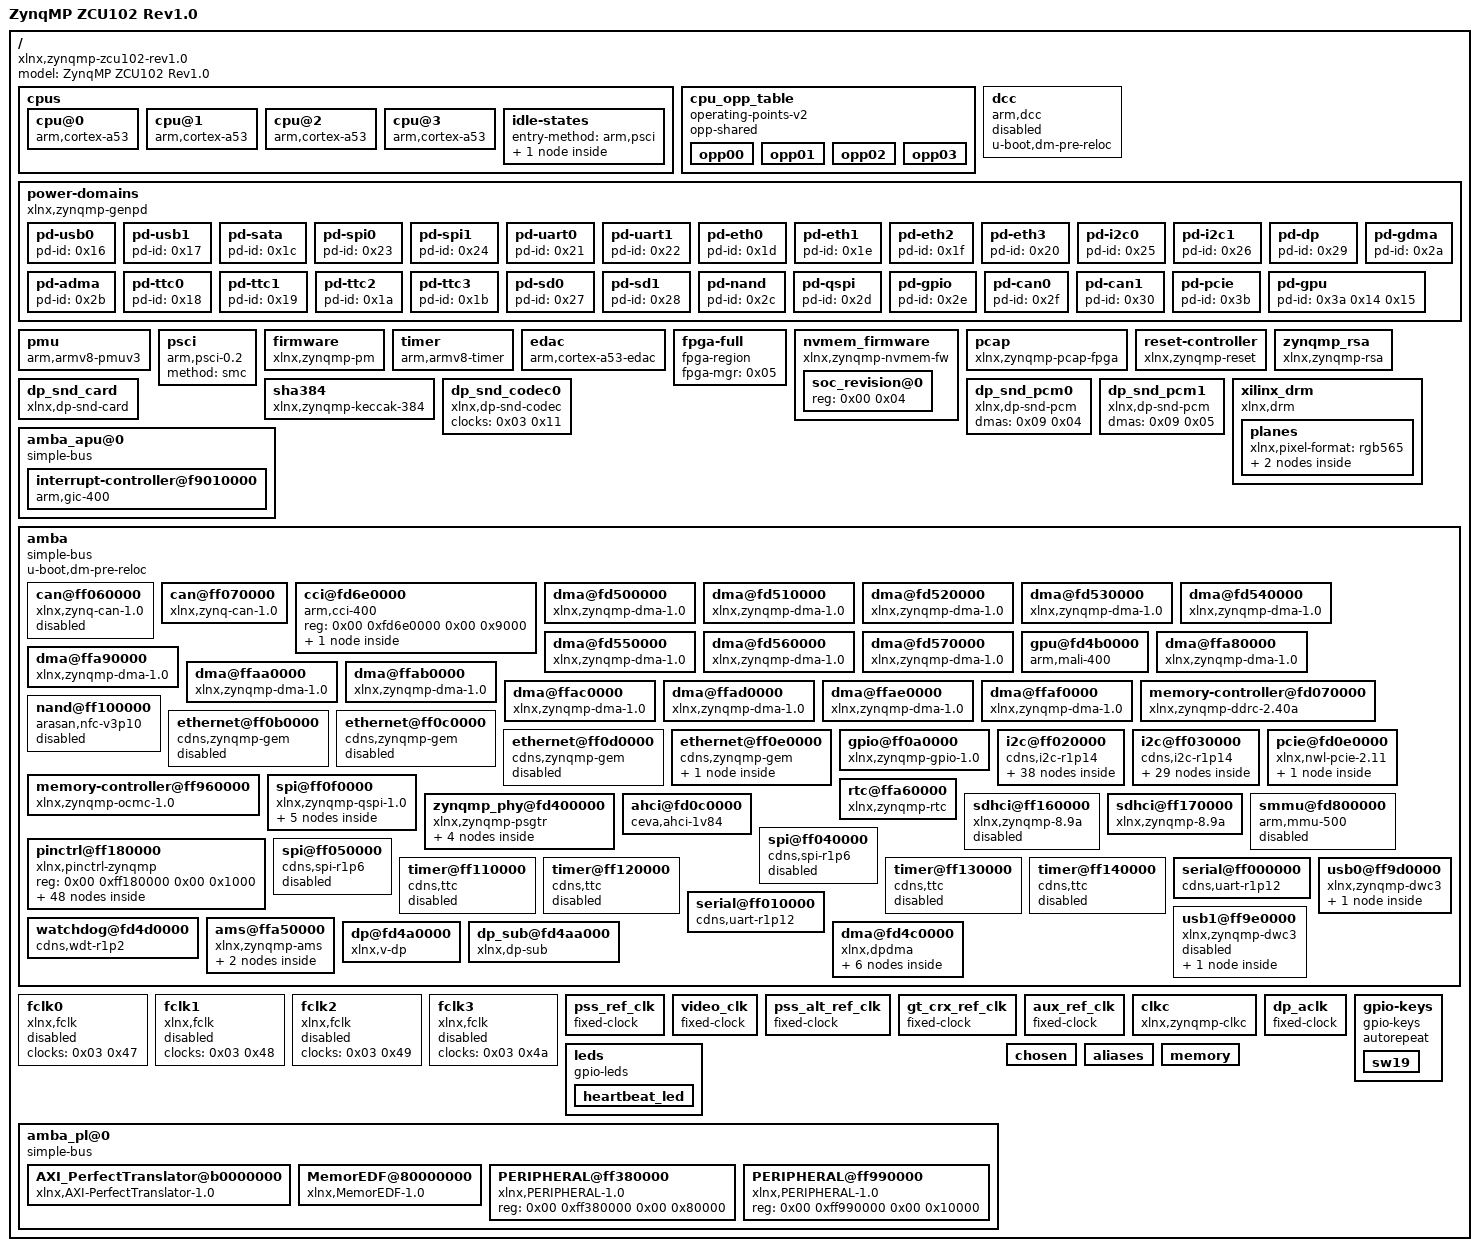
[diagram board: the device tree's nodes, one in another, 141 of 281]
/dts-v1/;

/ {
	compatible = "xlnx,zynqmp-zcu102-rev1.0\0xlnx,zynqmp-zcu102\0xlnx,zynqmp";
	#address-cells = < 0x02 >;
	#size-cells = < 0x02 >;
	model = "ZynqMP ZCU102 Rev1.0";

	cpus {
		#address-cells = < 0x01 >;
		#size-cells = < 0x00 >;

		cpu@0 {
			compatible = "arm,cortex-a53\0arm,armv8";
			device_type = "cpu";
			enable-method = "psci";
			operating-points-v2 = < 0x01 >;
			reg = < 0x00 >;
			cpu-idle-states = < 0x02 >;
			clocks = < 0x03 0x0a >;
		};

		cpu@1 {
			compatible = "arm,cortex-a53\0arm,armv8";
			device_type = "cpu";
			enable-method = "psci";
			reg = < 0x01 >;
			operating-points-v2 = < 0x01 >;
			cpu-idle-states = < 0x02 >;
		};

		cpu@2 {
			compatible = "arm,cortex-a53\0arm,armv8";
			device_type = "cpu";
			enable-method = "psci";
			reg = < 0x02 >;
			operating-points-v2 = < 0x01 >;
			cpu-idle-states = < 0x02 >;
		};

		cpu@3 {
			compatible = "arm,cortex-a53\0arm,armv8";
			device_type = "cpu";
			enable-method = "psci";
			reg = < 0x03 >;
			operating-points-v2 = < 0x01 >;
			cpu-idle-states = < 0x02 >;
		};

		idle-states {
			entry-method = "arm,psci";

			cpu-sleep-0 {
				compatible = "arm,idle-state";
				arm,psci-suspend-param = < 0x40000000 >;
				local-timer-stop;
				entry-latency-us = < 0x12c >;
				exit-latency-us = < 0x258 >;
				min-residency-us = < 0x2710 >;
				linux,phandle = < 0x02 >;
				phandle = < 0x02 >;
			};
		};
	};

	cpu_opp_table {
		compatible = "operating-points-v2";
		opp-shared;
		linux,phandle = < 0x01 >;
		phandle = < 0x01 >;

		opp00 {
			opp-hz = < 0x00 0x47868bf4 >;
			opp-microvolt = < 0xf4240 >;
			clock-latency-ns = < 0x7a120 >;
		};

		opp01 {
			opp-hz = < 0x00 0x23c345fa >;
			opp-microvolt = < 0xf4240 >;
			clock-latency-ns = < 0x7a120 >;
		};

		opp02 {
			opp-hz = < 0x00 0x17d783fc >;
			opp-microvolt = < 0xf4240 >;
			clock-latency-ns = < 0x7a120 >;
		};

		opp03 {
			opp-hz = < 0x00 0x11e1a2fd >;
			opp-microvolt = < 0xf4240 >;
			clock-latency-ns = < 0x7a120 >;
		};
	};

	dcc {
		compatible = "arm,dcc";
		status = "disabled";
		u-boot,dm-pre-reloc;
	};

	power-domains {
		compatible = "xlnx,zynqmp-genpd";

		pd-usb0 {
			#power-domain-cells = < 0x00 >;
			pd-id = < 0x16 >;
			linux,phandle = < 0x38 >;
			phandle = < 0x38 >;
		};

		pd-usb1 {
			#power-domain-cells = < 0x00 >;
			pd-id = < 0x17 >;
			linux,phandle = < 0x3b >;
			phandle = < 0x3b >;
		};

		pd-sata {
			#power-domain-cells = < 0x00 >;
			pd-id = < 0x1c >;
			linux,phandle = < 0x29 >;
			phandle = < 0x29 >;
		};

		pd-spi0 {
			#power-domain-cells = < 0x00 >;
			pd-id = < 0x23 >;
			linux,phandle = < 0x2e >;
			phandle = < 0x2e >;
		};

		pd-spi1 {
			#power-domain-cells = < 0x00 >;
			pd-id = < 0x24 >;
			linux,phandle = < 0x2f >;
			phandle = < 0x2f >;
		};

		pd-uart0 {
			#power-domain-cells = < 0x00 >;
			pd-id = < 0x21 >;
			linux,phandle = < 0x34 >;
			phandle = < 0x34 >;
		};

		pd-uart1 {
			#power-domain-cells = < 0x00 >;
			pd-id = < 0x22 >;
			linux,phandle = < 0x36 >;
			phandle = < 0x36 >;
		};

		pd-eth0 {
			#power-domain-cells = < 0x00 >;
			pd-id = < 0x1d >;
			linux,phandle = < 0x14 >;
			phandle = < 0x14 >;
		};

		pd-eth1 {
			#power-domain-cells = < 0x00 >;
			pd-id = < 0x1e >;
			linux,phandle = < 0x15 >;
			phandle = < 0x15 >;
		};

		pd-eth2 {
			#power-domain-cells = < 0x00 >;
			pd-id = < 0x1f >;
			linux,phandle = < 0x16 >;
			phandle = < 0x16 >;
		};

		pd-eth3 {
			#power-domain-cells = < 0x00 >;
			pd-id = < 0x20 >;
			linux,phandle = < 0x17 >;
			phandle = < 0x17 >;
		};

		pd-i2c0 {
			#power-domain-cells = < 0x00 >;
			pd-id = < 0x25 >;
			linux,phandle = < 0x1c >;
			phandle = < 0x1c >;
		};

		pd-i2c1 {
			#power-domain-cells = < 0x00 >;
			pd-id = < 0x26 >;
			linux,phandle = < 0x20 >;
			phandle = < 0x20 >;
		};

		pd-dp {
			#power-domain-cells = < 0x00 >;
			pd-id = < 0x29 >;
			linux,phandle = < 0x3c >;
			phandle = < 0x3c >;
		};

		pd-gdma {
			#power-domain-cells = < 0x00 >;
			pd-id = < 0x2a >;
			linux,phandle = < 0x10 >;
			phandle = < 0x10 >;
		};

		pd-adma {
			#power-domain-cells = < 0x00 >;
			pd-id = < 0x2b >;
			linux,phandle = < 0x12 >;
			phandle = < 0x12 >;
		};

		pd-ttc0 {
			#power-domain-cells = < 0x00 >;
			pd-id = < 0x18 >;
			linux,phandle = < 0x30 >;
			phandle = < 0x30 >;
		};

		pd-ttc1 {
			#power-domain-cells = < 0x00 >;
			pd-id = < 0x19 >;
			linux,phandle = < 0x31 >;
			phandle = < 0x31 >;
		};

		pd-ttc2 {
			#power-domain-cells = < 0x00 >;
			pd-id = < 0x1a >;
			linux,phandle = < 0x32 >;
			phandle = < 0x32 >;
		};

		pd-ttc3 {
			#power-domain-cells = < 0x00 >;
			pd-id = < 0x1b >;
			linux,phandle = < 0x33 >;
			phandle = < 0x33 >;
		};

		pd-sd0 {
			#power-domain-cells = < 0x00 >;
			pd-id = < 0x27 >;
			linux,phandle = < 0x2b >;
			phandle = < 0x2b >;
		};

		pd-sd1 {
			#power-domain-cells = < 0x00 >;
			pd-id = < 0x28 >;
			linux,phandle = < 0x2c >;
			phandle = < 0x2c >;
		};

		pd-nand {
			#power-domain-cells = < 0x00 >;
			pd-id = < 0x2c >;
			linux,phandle = < 0x13 >;
			phandle = < 0x13 >;
		};

		pd-qspi {
			#power-domain-cells = < 0x00 >;
			pd-id = < 0x2d >;
			linux,phandle = < 0x26 >;
			phandle = < 0x26 >;
		};

		pd-gpio {
			#power-domain-cells = < 0x00 >;
			pd-id = < 0x2e >;
			linux,phandle = < 0x1a >;
			phandle = < 0x1a >;
		};

		pd-can0 {
			#power-domain-cells = < 0x00 >;
			pd-id = < 0x2f >;
			linux,phandle = < 0x0c >;
			phandle = < 0x0c >;
		};

		pd-can1 {
			#power-domain-cells = < 0x00 >;
			pd-id = < 0x30 >;
			linux,phandle = < 0x0d >;
			phandle = < 0x0d >;
		};

		pd-pcie {
			#power-domain-cells = < 0x00 >;
			pd-id = < 0x3b >;
			linux,phandle = < 0x25 >;
			phandle = < 0x25 >;
		};

		pd-gpu {
			#power-domain-cells = < 0x00 >;
			pd-id = < 0x3a 0x14 0x15 >;
			linux,phandle = < 0x11 >;
			phandle = < 0x11 >;
		};
	};

	pmu {
		compatible = "arm,armv8-pmuv3";
		interrupt-parent = < 0x04 >;
		interrupts = < 0x00 0x8f 0x04 0x00 0x90 0x04 0x00 0x91 0x04 0x00 0x92 0x04 >;
	};

	psci {
		compatible = "arm,psci-0.2";
		method = "smc";
	};

	firmware {
		compatible = "xlnx,zynqmp-pm";
		method = "smc";
		interrupt-parent = < 0x04 >;
		interrupts = < 0x00 0x23 0x04 >;
	};

	timer {
		compatible = "arm,armv8-timer";
		interrupt-parent = < 0x04 >;
		interrupts = < 0x01 0x0d 0xf08 0x01 0x0e 0xf08 0x01 0x0b 0xf08 0x01 0x0a 0xf08 >;
	};

	edac {
		compatible = "arm,cortex-a53-edac";
	};

	fpga-full {
		compatible = "fpga-region";
		fpga-mgr = < 0x05 >;
		#address-cells = < 0x02 >;
		#size-cells = < 0x02 >;
	};

	nvmem_firmware {
		compatible = "xlnx,zynqmp-nvmem-fw";
		#address-cells = < 0x01 >;
		#size-cells = < 0x01 >;

		soc_revision@0 {
			reg = < 0x00 0x04 >;
			linux,phandle = < 0x27 >;
			phandle = < 0x27 >;
		};
	};

	pcap {
		compatible = "xlnx,zynqmp-pcap-fpga";
		linux,phandle = < 0x05 >;
		phandle = < 0x05 >;
	};

	reset-controller {
		compatible = "xlnx,zynqmp-reset";
		#reset-cells = < 0x01 >;
		linux,phandle = < 0x28 >;
		phandle = < 0x28 >;
	};

	zynqmp_rsa {
		compatible = "xlnx,zynqmp-rsa";
	};

	sha384 {
		compatible = "xlnx,zynqmp-keccak-384";
	};

	dp_snd_card {
		compatible = "xlnx,dp-snd-card";
		status = "okay";
		xlnx,dp-snd-pcm = < 0x06 0x07 >;
		xlnx,dp-snd-codec = < 0x08 >;
	};

	dp_snd_codec0 {
		compatible = "xlnx,dp-snd-codec";
		status = "okay";
		clock-names = "aud_clk";
		clocks = < 0x03 0x11 >;
		linux,phandle = < 0x08 >;
		phandle = < 0x08 >;
	};

	dp_snd_pcm0 {
		compatible = "xlnx,dp-snd-pcm";
		status = "okay";
		dmas = < 0x09 0x04 >;
		dma-names = "tx";
		linux,phandle = < 0x06 >;
		phandle = < 0x06 >;
	};

	dp_snd_pcm1 {
		compatible = "xlnx,dp-snd-pcm";
		status = "okay";
		dmas = < 0x09 0x05 >;
		dma-names = "tx";
		linux,phandle = < 0x07 >;
		phandle = < 0x07 >;
	};

	xilinx_drm {
		compatible = "xlnx,drm";
		status = "okay";
		xlnx,encoder-slave = < 0x0a >;
		xlnx,connector-type = "DisplayPort";
		xlnx,dp-sub = < 0x0b >;
		clocks = < 0x03 0x10 >;

		planes {
			xlnx,pixel-format = "rgb565";

			plane0 {
				dmas = < 0x09 0x03 >;
				dma-names = "dma0";
			};

			plane1 {
				dmas = < 0x09 0x00 0x09 0x01 0x09 0x02 >;
				dma-names = "dma0\0dma1\0dma2";
			};
		};
	};

	amba_apu@0 {
		compatible = "simple-bus";
		#address-cells = < 0x02 >;
		#size-cells = < 0x01 >;
		ranges = < 0x00 0x00 0x00 0x00 0xffffffff >;

		interrupt-controller@f9010000 {
			compatible = "arm,gic-400\0arm,cortex-a15-gic";
			#interrupt-cells = < 0x03 >;
			reg = < 0x00 0xf9010000 0x10000 0x00 0xf9020000 0x20000 0x00 0xf9040000 0x20000 0x00 0xf9060000 0x20000 >;
			interrupt-controller;
			interrupt-parent = < 0x04 >;
			interrupts = < 0x01 0x09 0xf04 >;
			linux,phandle = < 0x04 >;
			phandle = < 0x04 >;
		};
	};

	amba {
		compatible = "simple-bus";
		u-boot,dm-pre-reloc;
		#address-cells = < 0x02 >;
		#size-cells = < 0x02 >;
		ranges;

		can@ff060000 {
			compatible = "xlnx,zynq-can-1.0";
			status = "disabled";
			clock-names = "can_clk\0pclk";
			reg = < 0x00 0xff060000 0x00 0x1000 >;
			interrupts = < 0x00 0x17 0x04 >;
			interrupt-parent = < 0x04 >;
			tx-fifo-depth = < 0x40 >;
			rx-fifo-depth = < 0x40 >;
			power-domains = < 0x0c >;
			clocks = < 0x03 0x3f 0x03 0x1f >;
		};

		can@ff070000 {
			compatible = "xlnx,zynq-can-1.0";
			status = "okay";
			clock-names = "can_clk\0pclk";
			reg = < 0x00 0xff070000 0x00 0x1000 >;
			interrupts = < 0x00 0x18 0x04 >;
			interrupt-parent = < 0x04 >;
			tx-fifo-depth = < 0x40 >;
			rx-fifo-depth = < 0x40 >;
			power-domains = < 0x0d >;
			clocks = < 0x03 0x40 0x03 0x1f >;
			pinctrl-names = "default";
			pinctrl-0 = < 0x0e >;
		};

		cci@fd6e0000 {
			compatible = "arm,cci-400";
			reg = < 0x00 0xfd6e0000 0x00 0x9000 >;
			ranges = < 0x00 0x00 0xfd6e0000 0x10000 >;
			#address-cells = < 0x01 >;
			#size-cells = < 0x01 >;

			pmu@9000 {
				compatible = "arm,cci-400-pmu,r1";
				reg = < 0x9000 0x5000 >;
				interrupt-parent = < 0x04 >;
				interrupts = < 0x00 0x7b 0x04 0x00 0x7b 0x04 0x00 0x7b 0x04 0x00 0x7b 0x04 0x00 0x7b 0x04 >;
			};
		};

		dma@fd500000 {
			status = "okay";
			compatible = "xlnx,zynqmp-dma-1.0";
			reg = < 0x00 0xfd500000 0x00 0x1000 >;
			interrupt-parent = < 0x04 >;
			interrupts = < 0x00 0x7c 0x04 >;
			clock-names = "clk_main\0clk_apb";
			xlnx,bus-width = < 0x80 >;
			#stream-id-cells = < 0x01 >;
			iommus = < 0x0f 0x14e8 >;
			power-domains = < 0x10 >;
			clocks = < 0x03 0x13 0x03 0x1f >;
			xlnx,include-sg;
			xlnx,overfetch;
			xlnx,ratectrl = < 0x00 >;
			xlnx,src-issue = < 0x1f >;
		};

		dma@fd510000 {
			status = "okay";
			compatible = "xlnx,zynqmp-dma-1.0";
			reg = < 0x00 0xfd510000 0x00 0x1000 >;
			interrupt-parent = < 0x04 >;
			interrupts = < 0x00 0x7d 0x04 >;
			clock-names = "clk_main\0clk_apb";
			xlnx,bus-width = < 0x80 >;
			#stream-id-cells = < 0x01 >;
			iommus = < 0x0f 0x14e9 >;
			power-domains = < 0x10 >;
			clocks = < 0x03 0x13 0x03 0x1f >;
			xlnx,ratectrl = < 0x64 >;
			xlnx,src-issue = < 0x04 >;
		};

		dma@fd520000 {
			status = "okay";
			compatible = "xlnx,zynqmp-dma-1.0";
			reg = < 0x00 0xfd520000 0x00 0x1000 >;
			interrupt-parent = < 0x04 >;
			interrupts = < 0x00 0x7e 0x04 >;
			clock-names = "clk_main\0clk_apb";
			xlnx,bus-width = < 0x80 >;
			#stream-id-cells = < 0x01 >;
			iommus = < 0x0f 0x14ea >;
			power-domains = < 0x10 >;
			clocks = < 0x03 0x13 0x03 0x1f >;
		};

		dma@fd530000 {
			status = "okay";
			compatible = "xlnx,zynqmp-dma-1.0";
			reg = < 0x00 0xfd530000 0x00 0x1000 >;
			interrupt-parent = < 0x04 >;
			interrupts = < 0x00 0x7f 0x04 >;
			clock-names = "clk_main\0clk_apb";
			xlnx,bus-width = < 0x80 >;
			#stream-id-cells = < 0x01 >;
			iommus = < 0x0f 0x14eb >;
			power-domains = < 0x10 >;
			clocks = < 0x03 0x13 0x03 0x1f >;
			xlnx,include-sg;
		};

		dma@fd540000 {
			status = "okay";
			compatible = "xlnx,zynqmp-dma-1.0";
			reg = < 0x00 0xfd540000 0x00 0x1000 >;
			interrupt-parent = < 0x04 >;
			interrupts = < 0x00 0x80 0x04 >;
			clock-names = "clk_main\0clk_apb";
			xlnx,bus-width = < 0x80 >;
			#stream-id-cells = < 0x01 >;
			iommus = < 0x0f 0x14ec >;
			power-domains = < 0x10 >;
			clocks = < 0x03 0x13 0x03 0x1f >;
		};

		dma@fd550000 {
			status = "okay";
			compatible = "xlnx,zynqmp-dma-1.0";
			reg = < 0x00 0xfd550000 0x00 0x1000 >;
			interrupt-parent = < 0x04 >;
			interrupts = < 0x00 0x81 0x04 >;
			clock-names = "clk_main\0clk_apb";
			xlnx,bus-width = < 0x80 >;
			#stream-id-cells = < 0x01 >;
			iommus = < 0x0f 0x14ed >;
			power-domains = < 0x10 >;
			clocks = < 0x03 0x13 0x03 0x1f >;
			xlnx,include-sg;
		};

		dma@fd560000 {
			status = "okay";
			compatible = "xlnx,zynqmp-dma-1.0";
			reg = < 0x00 0xfd560000 0x00 0x1000 >;
			interrupt-parent = < 0x04 >;
			interrupts = < 0x00 0x82 0x04 >;
			clock-names = "clk_main\0clk_apb";
			xlnx,bus-width = < 0x80 >;
			#stream-id-cells = < 0x01 >;
			iommus = < 0x0f 0x14ee >;
			power-domains = < 0x10 >;
			clocks = < 0x03 0x13 0x03 0x1f >;
		};

		dma@fd570000 {
			status = "okay";
			compatible = "xlnx,zynqmp-dma-1.0";
			reg = < 0x00 0xfd570000 0x00 0x1000 >;
			interrupt-parent = < 0x04 >;
			interrupts = < 0x00 0x83 0x04 >;
			clock-names = "clk_main\0clk_apb";
			xlnx,bus-width = < 0x80 >;
			#stream-id-cells = < 0x01 >;
			iommus = < 0x0f 0x14ef >;
			power-domains = < 0x10 >;
			clocks = < 0x03 0x13 0x03 0x1f >;
			xlnx,include-sg;
		};

		gpu@fd4b0000 {
			status = "okay";
			compatible = "arm,mali-400\0arm,mali-utgard";
			reg = < 0x00 0xfd4b0000 0x00 0x10000 >;
			interrupt-parent = < 0x04 >;
			interrupts = < 0x00 0x84 0x04 0x00 0x84 0x04 0x00 0x84 0x04 0x00 0x84 0x04 0x00 0x84 0x04 0x00 0x84 0x04 >;
			interrupt-names = "IRQGP\0IRQGPMMU\0IRQPP0\0IRQPPMMU0\0IRQPP1\0IRQPPMMU1";
			clock-names = "gpu\0gpu_pp0\0gpu_pp1";
			power-domains = < 0x11 >;
			clocks = < 0x03 0x18 0x03 0x19 0x03 0x1a >;
		};

		dma@ffa80000 {
			status = "okay";
			compatible = "xlnx,zynqmp-dma-1.0";
			clock-names = "clk_main\0clk_apb";
			reg = < 0x00 0xffa80000 0x00 0x1000 >;
			interrupt-parent = < 0x04 >;
			interrupts = < 0x00 0x4d 0x04 >;
			xlnx,bus-width = < 0x40 >;
			#stream-id-cells = < 0x01 >;
			power-domains = < 0x12 >;
			clocks = < 0x03 0x44 0x03 0x1f >;
		};

		dma@ffa90000 {
			status = "okay";
			compatible = "xlnx,zynqmp-dma-1.0";
			clock-names = "clk_main\0clk_apb";
			reg = < 0x00 0xffa90000 0x00 0x1000 >;
			interrupt-parent = < 0x04 >;
			interrupts = < 0x00 0x4e 0x04 >;
			xlnx,bus-width = < 0x40 >;
			#stream-id-cells = < 0x01 >;
			power-domains = < 0x12 >;
			clocks = < 0x03 0x44 0x03 0x1f >;
		};

		dma@ffaa0000 {
			status = "okay";
			compatible = "xlnx,zynqmp-dma-1.0";
			clock-names = "clk_main\0clk_apb";
			reg = < 0x00 0xffaa0000 0x00 0x1000 >;
			interrupt-parent = < 0x04 >;
			interrupts = < 0x00 0x4f 0x04 >;
			xlnx,bus-width = < 0x40 >;
			#stream-id-cells = < 0x01 >;
			power-domains = < 0x12 >;
			clocks = < 0x03 0x44 0x03 0x1f >;
		};

		dma@ffab0000 {
			status = "okay";
			compatible = "xlnx,zynqmp-dma-1.0";
			clock-names = "clk_main\0clk_apb";
			reg = < 0x00 0xffab0000 0x00 0x1000 >;
			interrupt-parent = < 0x04 >;
			interrupts = < 0x00 0x50 0x04 >;
			xlnx,bus-width = < 0x40 >;
			#stream-id-cells = < 0x01 >;
			power-domains = < 0x12 >;
			clocks = < 0x03 0x44 0x03 0x1f >;
		};

		dma@ffac0000 {
			status = "okay";
			compatible = "xlnx,zynqmp-dma-1.0";
			clock-names = "clk_main\0clk_apb";
			reg = < 0x00 0xffac0000 0x00 0x1000 >;
			interrupt-parent = < 0x04 >;
			interrupts = < 0x00 0x51 0x04 >;
			xlnx,bus-width = < 0x40 >;
			#stream-id-cells = < 0x01 >;
			power-domains = < 0x12 >;
			clocks = < 0x03 0x44 0x03 0x1f >;
		};

		dma@ffad0000 {
			status = "okay";
			compatible = "xlnx,zynqmp-dma-1.0";
			clock-names = "clk_main\0clk_apb";
			reg = < 0x00 0xffad0000 0x00 0x1000 >;
			interrupt-parent = < 0x04 >;
			interrupts = < 0x00 0x52 0x04 >;
			xlnx,bus-width = < 0x40 >;
			#stream-id-cells = < 0x01 >;
			power-domains = < 0x12 >;
			clocks = < 0x03 0x44 0x03 0x1f >;
		};

		dma@ffae0000 {
			status = "okay";
			compatible = "xlnx,zynqmp-dma-1.0";
			clock-names = "clk_main\0clk_apb";
			reg = < 0x00 0xffae0000 0x00 0x1000 >;
			interrupt-parent = < 0x04 >;
			interrupts = < 0x00 0x53 0x04 >;
			xlnx,bus-width = < 0x40 >;
			#stream-id-cells = < 0x01 >;
			power-domains = < 0x12 >;
			clocks = < 0x03 0x44 0x03 0x1f >;
		};

		dma@ffaf0000 {
			status = "okay";
			compatible = "xlnx,zynqmp-dma-1.0";
			clock-names = "clk_main\0clk_apb";
			reg = < 0x00 0xffaf0000 0x00 0x1000 >;
			interrupt-parent = < 0x04 >;
			interrupts = < 0x00 0x54 0x04 >;
			xlnx,bus-width = < 0x40 >;
			#stream-id-cells = < 0x01 >;
			power-domains = < 0x12 >;
			clocks = < 0x03 0x44 0x03 0x1f >;
		};

		memory-controller@fd070000 {
			compatible = "xlnx,zynqmp-ddrc-2.40a";
			reg = < 0x00 0xfd070000 0x00 0x30000 >;
			interrupt-parent = < 0x04 >;
			interrupts = < 0x00 0x70 0x04 >;
		};

		nand@ff100000 {
			compatible = "arasan,nfc-v3p10";
			status = "disabled";
			reg = < 0x00 0xff100000 0x00 0x1000 >;
			clock-names = "clk_sys\0clk_flash";
			interrupt-parent = < 0x04 >;
			interrupts = < 0x00 0x0e 0x04 >;
			#address-cells = < 0x01 >;
			#size-cells = < 0x00 >;
			#stream-id-cells = < 0x01 >;
			iommus = < 0x0f 0x872 >;
			power-domains = < 0x13 >;
			clocks = < 0x03 0x3c 0x03 0x1f >;
		};

		ethernet@ff0b0000 {
			compatible = "cdns,zynqmp-gem";
			status = "disabled";
			interrupt-parent = < 0x04 >;
			interrupts = < 0x00 0x39 0x04 0x00 0x39 0x04 >;
			reg = < 0x00 0xff0b0000 0x00 0x1000 >;
			clock-names = "pclk\0tx_clk\0hclk";
			#address-cells = < 0x01 >;
			#size-cells = < 0x00 >;
			#stream-id-cells = < 0x01 >;
			iommus = < 0x0f 0x874 >;
			power-domains = < 0x14 >;
			clocks = < 0x03 0x2d 0x03 0x2d 0x03 0x31 >;
		};

		ethernet@ff0c0000 {
			compatible = "cdns,zynqmp-gem";
			status = "disabled";
			interrupt-parent = < 0x04 >;
			interrupts = < 0x00 0x3b 0x04 0x00 0x3b 0x04 >;
			reg = < 0x00 0xff0c0000 0x00 0x1000 >;
			clock-names = "pclk\0tx_clk\0hclk";
			#address-cells = < 0x01 >;
			#size-cells = < 0x00 >;
			#stream-id-cells = < 0x01 >;
			iommus = < 0x0f 0x875 >;
			power-domains = < 0x15 >;
			clocks = < 0x03 0x2e 0x03 0x2e 0x03 0x32 >;
		};

		ethernet@ff0d0000 {
			compatible = "cdns,zynqmp-gem";
			status = "disabled";
			interrupt-parent = < 0x04 >;
			interrupts = < 0x00 0x3d 0x04 0x00 0x3d 0x04 >;
			reg = < 0x00 0xff0d0000 0x00 0x1000 >;
			clock-names = "pclk\0tx_clk\0hclk";
			#address-cells = < 0x01 >;
			#size-cells = < 0x00 >;
			#stream-id-cells = < 0x01 >;
			iommus = < 0x0f 0x876 >;
			power-domains = < 0x16 >;
			clocks = < 0x03 0x2f 0x03 0x2f 0x03 0x33 >;
		};

		ethernet@ff0e0000 {
			compatible = "cdns,zynqmp-gem";
			status = "okay";
			interrupt-parent = < 0x04 >;
			interrupts = < 0x00 0x3f 0x04 0x00 0x3f 0x04 >;
			reg = < 0x00 0xff0e0000 0x00 0x1000 >;
			clock-names = "pclk\0hclk\0tx_clk\0rx_clk";
			#address-cells = < 0x01 >;
			#size-cells = < 0x00 >;
			#stream-id-cells = < 0x01 >;
			iommus = < 0x0f 0x877 >;
			power-domains = < 0x17 >;
			clocks = < 0x03 0x1f 0x03 0x34 0x03 0x30 0x03 0x34 >;
			phy-handle = < 0x18 >;
			pinctrl-names = "default";
			pinctrl-0 = < 0x19 >;
			phy-mode = "rgmii-id";
			xlnx,ptp-enet-clock = < 0x00 >;
			local-mac-address = [ 00 0a 35 00 22 01 ];

			phy@c {
				reg = < 0x0c >;
				ti,rx-internal-delay = < 0x08 >;
				ti,tx-internal-delay = < 0x0a >;
				ti,fifo-depth = < 0x01 >;
				ti,rxctrl-strap-worka;
				linux,phandle = < 0x18 >;
				phandle = < 0x18 >;
			};
		};

		gpio@ff0a0000 {
			compatible = "xlnx,zynqmp-gpio-1.0";
			status = "okay";
			#gpio-cells = < 0x02 >;
			interrupt-parent = < 0x04 >;
			interrupts = < 0x00 0x10 0x04 >;
			interrupt-controller;
			#interrupt-cells = < 0x02 >;
			reg = < 0x00 0xff0a0000 0x00 0x1000 >;
			gpio-controller;
			power-domains = < 0x1a >;
			clocks = < 0x03 0x1f >;
			pinctrl-names = "default";
			pinctrl-0 = < 0x1b >;
			emio-gpio-width = < 0x20 >;
			gpio-mask-high = < 0x00 >;
			gpio-mask-low = < 0x5600 >;
			linux,phandle = < 0x1f >;
			phandle = < 0x1f >;
		};

		i2c@ff020000 {
			compatible = "cdns,i2c-r1p14\0cdns,i2c-r1p10";
			status = "okay";
			interrupt-parent = < 0x04 >;
			interrupts = < 0x00 0x11 0x04 >;
			reg = < 0x00 0xff020000 0x00 0x1000 >;
			#address-cells = < 0x01 >;
			#size-cells = < 0x00 >;
			power-domains = < 0x1c >;
			clocks = < 0x03 0x3d >;
			pinctrl-names = "default\0gpio";
			pinctrl-0 = < 0x1d >;
			pinctrl-1 = < 0x1e >;
			scl-gpios = < 0x1f 0x0e 0x00 >;
			sda-gpios = < 0x1f 0x0f 0x00 >;
			clock-frequency = < 0x61a80 >;

			gpio@20 {
				compatible = "ti,tca6416";
				reg = < 0x20 >;
				gpio-controller;
				#gpio-cells = < 0x02 >;
			};

			gpio@21 {
				compatible = "ti,tca6416";
				reg = < 0x21 >;
				gpio-controller;
				#gpio-cells = < 0x02 >;
			};

			i2cswitch@75 {
				compatible = "nxp,pca9544";
				#address-cells = < 0x01 >;
				#size-cells = < 0x00 >;
				reg = < 0x75 >;

				i2c@0 {
					#address-cells = < 0x01 >;
					#size-cells = < 0x00 >;
					reg = < 0x00 >;

					ina226@40 {
						compatible = "ti,ina226";
						reg = < 0x40 >;
						shunt-resistor = < 0x1388 >;
					};

					ina226@41 {
						compatible = "ti,ina226";
						reg = < 0x41 >;
						shunt-resistor = < 0x1388 >;
					};

					ina226@42 {
						compatible = "ti,ina226";
						reg = < 0x42 >;
						shunt-resistor = < 0x1388 >;
					};

					ina226@43 {
						compatible = "ti,ina226";
						reg = < 0x43 >;
						shunt-resistor = < 0x1388 >;
					};

					ina226@44 {
						compatible = "ti,ina226";
						reg = < 0x44 >;
						shunt-resistor = < 0x1388 >;
					};

					ina226@45 {
						compatible = "ti,ina226";
						reg = < 0x45 >;
						shunt-resistor = < 0x1388 >;
					};

					ina226@46 {
						compatible = "ti,ina226";
						reg = < 0x46 >;
						shunt-resistor = < 0x1388 >;
					};

					ina226@47 {
						compatible = "ti,ina226";
						reg = < 0x47 >;
						shunt-resistor = < 0x1388 >;
					};

					ina226@4a {
						compatible = "ti,ina226";
						reg = < 0x4a >;
						shunt-resistor = < 0x1388 >;
					};

					ina226@4b {
						compatible = "ti,ina226";
						reg = < 0x4b >;
						shunt-resistor = < 0x1388 >;
					};
				};

				i2c@1 {
					#address-cells = < 0x01 >;
					#size-cells = < 0x00 >;
					reg = < 0x01 >;

					ina226@40 {
						compatible = "ti,ina226";
						reg = < 0x40 >;
						shunt-resistor = < 0x7d0 >;
					};

					ina226@41 {
						compatible = "ti,ina226";
						reg = < 0x41 >;
						shunt-resistor = < 0x1388 >;
					};

					ina226@42 {
						compatible = "ti,ina226";
						reg = < 0x42 >;
						shunt-resistor = < 0x1388 >;
					};

					ina226@43 {
						compatible = "ti,ina226";
						reg = < 0x43 >;
						shunt-resistor = < 0x1388 >;
					};

					ina226@44 {
						compatible = "ti,ina226";
						reg = < 0x44 >;
						shunt-resistor = < 0x1388 >;
					};

					ina226@45 {
						compatible = "ti,ina226";
						reg = < 0x45 >;
						shunt-resistor = < 0x1388 >;
					};

					ina226@46 {
						compatible = "ti,ina226";
						reg = < 0x46 >;
						shunt-resistor = < 0x1388 >;
					};

					ina226@47 {
						compatible = "ti,ina226";
						reg = < 0x47 >;
						shunt-resistor = < 0x1388 >;
					};
				};

				i2c@2 {
					#address-cells = < 0x01 >;
					#size-cells = < 0x00 >;
					reg = < 0x02 >;

					max15301@a {
						compatible = "max15301";
						reg = < 0x0a >;
					};

					max15303@b {
						compatible = "max15303";
						reg = < 0x0b >;
					};

					max15303@10 {
						compatible = "max15303";
						reg = < 0x10 >;
					};

					max15301@13 {
						compatible = "max15301";
						reg = < 0x13 >;
					};

					max15303@14 {
						compatible = "max15303";
						reg = < 0x14 >;
					};

					max15303@15 {
						compatible = "max15303";
						reg = < 0x15 >;
					};

					max15303@16 {
						compatible = "max15303";
						reg = < 0x16 >;
					};

					max15303@17 {
						compatible = "max15303";
						reg = < 0x17 >;
					};

					max15301@18 {
						compatible = "max15301";
						reg = < 0x18 >;
					};

					max15303@1a {
						compatible = "max15303";
						reg = < 0x1a >;
					};

					max15303@1b {
						compatible = "max15303";
						reg = < 0x1b >;
					};

					max15303@1d {
						compatible = "max15303";
						reg = < 0x1d >;
					};

					max20751@72 {
						compatible = "max20751";
						reg = < 0x72 >;
					};

					max20751@73 {
						compatible = "max20751";
						reg = < 0x73 >;
					};
				};
			};
		};

		i2c@ff030000 {
			compatible = "cdns,i2c-r1p14\0cdns,i2c-r1p10";
			status = "okay";
			interrupt-parent = < 0x04 >;
			interrupts = < 0x00 0x12 0x04 >;
			reg = < 0x00 0xff030000 0x00 0x1000 >;
			#address-cells = < 0x01 >;
			#size-cells = < 0x00 >;
			power-domains = < 0x20 >;
			clocks = < 0x03 0x3e >;
			pinctrl-names = "default\0gpio";
			pinctrl-0 = < 0x21 >;
			pinctrl-1 = < 0x22 >;
			scl-gpios = < 0x1f 0x10 0x00 >;
			sda-gpios = < 0x1f 0x11 0x00 >;
			clock-frequency = < 0x61a80 >;

			i2cswitch@74 {
				compatible = "nxp,pca9548";
				#address-cells = < 0x01 >;
				#size-cells = < 0x00 >;
				reg = < 0x74 >;

				i2c@0 {
					#address-cells = < 0x01 >;
					#size-cells = < 0x00 >;
					reg = < 0x00 >;

					eeprom@54 {
						compatible = "at,24c08";
						reg = < 0x54 >;
						#address-cells = < 0x01 >;
						#size-cells = < 0x01 >;

						board_sn@0 {
							reg = < 0x00 0x14 >;
						};

						eth_mac@20 {
							reg = < 0x20 0x06 >;
						};

						board_name@d0 {
							reg = < 0xd0 0x06 >;
						};

						board_revision@e0 {
							reg = < 0xe0 0x03 >;
						};
					};
				};

				i2c@1 {
					#address-cells = < 0x01 >;
					#size-cells = < 0x00 >;
					reg = < 0x01 >;

					clock-generator1@36 {
						compatible = "si5341";
						reg = < 0x36 >;
					};
				};

				i2c@2 {
					#address-cells = < 0x01 >;
					#size-cells = < 0x00 >;
					reg = < 0x02 >;

					clock-generator2@5d {
						#clock-cells = < 0x00 >;
						compatible = "silabs,si570";
						reg = < 0x5d >;
						temperature-stability = < 0x32 >;
						factory-fout = < 0x11e1a300 >;
						clock-frequency = < 0x11e1a300 >;
					};
				};

				i2c@3 {
					#address-cells = < 0x01 >;
					#size-cells = < 0x00 >;
					reg = < 0x03 >;

					clock-generator3@5d {
						#clock-cells = < 0x00 >;
						compatible = "silabs,si570";
						reg = < 0x5d >;
						temperature-stability = < 0x32 >;
						factory-fout = < 0x9502f90 >;
						clock-frequency = < 0x8d9ee20 >;
					};
				};

				i2c@4 {
					#address-cells = < 0x01 >;
					#size-cells = < 0x00 >;
					reg = < 0x04 >;

					clock-generator4@69 {
						compatible = "silabs,si5328";
						reg = < 0x69 >;
					};
				};
			};

			i2cswitch@75 {
				compatible = "nxp,pca9548";
				#address-cells = < 0x01 >;
				#size-cells = < 0x00 >;
				reg = < 0x75 >;

				i2c@0 {
					#address-cells = < 0x01 >;
					#size-cells = < 0x00 >;
					reg = < 0x00 >;
				};

				i2c@1 {
					#address-cells = < 0x01 >;
					#size-cells = < 0x00 >;
					reg = < 0x01 >;
				};

				i2c@2 {
					#address-cells = < 0x01 >;
					#size-cells = < 0x00 >;
					reg = < 0x02 >;
				};

				i2c@3 {
					#address-cells = < 0x01 >;
					#size-cells = < 0x00 >;
					reg = < 0x03 >;

					dev@19 {
						compatible = "xxx";
						reg = < 0x19 >;
					};

					dev@30 {
						compatible = "xxx";
						reg = < 0x30 >;
					};

					dev@35 {
						compatible = "xxx";
						reg = < 0x35 >;
					};

					dev@36 {
						compatible = "xxx";
						reg = < 0x36 >;
					};

					dev@51 {
						compatible = "xxx";
						reg = < 0x51 >;
					};
				};

				i2c@4 {
					#address-cells = < 0x01 >;
					#size-cells = < 0x00 >;
					reg = < 0x04 >;
				};

				i2c@5 {
					#address-cells = < 0x01 >;
					#size-cells = < 0x00 >;
					reg = < 0x05 >;
				};

				i2c@6 {
					#address-cells = < 0x01 >;
					#size-cells = < 0x00 >;
					reg = < 0x06 >;
				};

				i2c@7 {
					#address-cells = < 0x01 >;
					#size-cells = < 0x00 >;
					reg = < 0x07 >;
				};
			};
		};

		memory-controller@ff960000 {
			compatible = "xlnx,zynqmp-ocmc-1.0";
			reg = < 0x00 0xff960000 0x00 0x1000 >;
			interrupt-parent = < 0x04 >;
			interrupts = < 0x00 0x0a 0x04 >;
		};

		pcie@fd0e0000 {
			compatible = "xlnx,nwl-pcie-2.11";
			status = "okay";
			#address-cells = < 0x03 >;
			#size-cells = < 0x02 >;
			#interrupt-cells = < 0x01 >;
			msi-controller;
			device_type = "pci";
			interrupt-parent = < 0x04 >;
			interrupts = < 0x00 0x76 0x04 0x00 0x75 0x04 0x00 0x74 0x04 0x00 0x73 0x04 0x00 0x72 0x04 >;
			interrupt-names = "misc\0dummy\0intx\0msi1\0msi0";
			msi-parent = < 0x23 >;
			reg = < 0x00 0xfd0e0000 0x00 0x1000 0x00 0xfd480000 0x00 0x1000 0x80 0x00 0x00 0x1000000 >;
			reg-names = "breg\0pcireg\0cfg";
			ranges = < 0x2000000 0x00 0xe0000000 0x00 0xe0000000 0x00 0x10000000 0x43000000 0x06 0x00 0x06 0x00 0x02 0x00 >;
			interrupt-map-mask = < 0x00 0x00 0x00 0x07 >;
			bus-range = < 0x00 0xff >;
			interrupt-map = < 0x00 0x00 0x00 0x01 0x24 0x01 0x00 0x00 0x00 0x02 0x24 0x02 0x00 0x00 0x00 0x03 0x24 0x03 0x00 0x00 0x00 0x04 0x24 0x04 >;
			power-domains = < 0x25 >;
			clocks = < 0x03 0x17 >;
			xlnx,pcie-mode = "Root Port";
			linux,phandle = < 0x23 >;
			phandle = < 0x23 >;

			legacy-interrupt-controller {
				interrupt-controller;
				#address-cells = < 0x00 >;
				#interrupt-cells = < 0x01 >;
				linux,phandle = < 0x24 >;
				phandle = < 0x24 >;
			};
		};

		spi@ff0f0000 {
			u-boot,dm-pre-reloc;
			compatible = "xlnx,zynqmp-qspi-1.0";
			status = "okay";
			clock-names = "ref_clk\0pclk";
			interrupts = < 0x00 0x0f 0x04 >;
			interrupt-parent = < 0x04 >;
			num-cs = < 0x01 >;
			reg = < 0x00 0xff0f0000 0x00 0x1000 0x00 0xc0000000 0x00 0x8000000 >;
			#address-cells = < 0x01 >;
			#size-cells = < 0x00 >;
			#stream-id-cells = < 0x01 >;
			iommus = < 0x0f 0x873 >;
			power-domains = < 0x26 >;
			clocks = < 0x03 0x35 0x03 0x1f >;
			is-dual = < 0x01 >;
			spi-rx-bus-width = < 0x04 >;
			spi-tx-bus-width = < 0x04 >;

			flash@0 {
				compatible = "n25q512a\0micron,m25p80";
				#address-cells = < 0x01 >;
				#size-cells = < 0x01 >;
				reg = < 0x00 >;
				spi-tx-bus-width = < 0x01 >;
				spi-rx-bus-width = < 0x04 >;
				spi-max-frequency = < 0x66ff300 >;

				partition@0x00000000 {
					label = "boot";
					reg = < 0x00 0x1e00000 >;
				};

				partition@0x01e00000 {
					label = "bootenv";
					reg = < 0x1e00000 0x40000 >;
				};

				partition@0x01e40000 {
					label = "kernel";
					reg = < 0x1e40000 0x2400000 >;
				};

				partition@0x04240000 {
					label = "spare";
					reg = < 0x4240000 0x00 >;
				};
			};
		};

		rtc@ffa60000 {
			compatible = "xlnx,zynqmp-rtc";
			status = "okay";
			reg = < 0x00 0xffa60000 0x00 0x100 >;
			interrupt-parent = < 0x04 >;
			interrupts = < 0x00 0x1a 0x04 0x00 0x1b 0x04 >;
			interrupt-names = "alarm\0sec";
			calibration = < 0x8000 >;
		};

		zynqmp_phy@fd400000 {
			compatible = "xlnx,zynqmp-psgtr";
			status = "okay";
			reg = < 0x00 0xfd400000 0x00 0x40000 0x00 0xfd3d0000 0x00 0x1000 0x00 0xff5e0000 0x00 0x1000 >;
			reg-names = "serdes\0siou\0lpd";
			nvmem-cells = < 0x27 >;
			nvmem-cell-names = "soc_revision";
			resets = < 0x28 0x10 0x28 0x3b 0x28 0x3c 0x28 0x3d 0x28 0x3e 0x28 0x3f 0x28 0x40 0x28 0x03 0x28 0x1d 0x28 0x1e 0x28 0x1f 0x28 0x20 >;
			reset-names = "sata_rst\0usb0_crst\0usb1_crst\0usb0_hibrst\0usb1_hibrst\0usb0_apbrst\0usb1_apbrst\0dp_rst\0gem0_rst\0gem1_rst\0gem2_rst\0gem3_rst";

			lane0 {
				#phy-cells = < 0x04 >;
			};

			lane1 {
				#phy-cells = < 0x04 >;
				linux,phandle = < 0x3e >;
				phandle = < 0x3e >;
			};

			lane2 {
				#phy-cells = < 0x04 >;
				linux,phandle = < 0x3a >;
				phandle = < 0x3a >;
			};

			lane3 {
				#phy-cells = < 0x04 >;
				linux,phandle = < 0x2a >;
				phandle = < 0x2a >;
			};
		};

		ahci@fd0c0000 {
			compatible = "ceva,ahci-1v84";
			status = "okay";
			reg = < 0x00 0xfd0c0000 0x00 0x2000 >;
			interrupt-parent = < 0x04 >;
			interrupts = < 0x00 0x85 0x04 >;
			power-domains = < 0x29 >;
			#stream-id-cells = < 0x04 >;
			iommus = < 0x0f 0x4c0 0x0f 0x4c1 0x0f 0x4c2 0x0f 0x4c3 >;
			clocks = < 0x03 0x16 >;
			ceva,p0-cominit-params = < 0x18401828 >;
			ceva,p0-comwake-params = < 0x614080e >;
			ceva,p0-burst-params = < 0x13084a06 >;
			ceva,p0-retry-params = < 0x96a43ffc >;
			ceva,p1-cominit-params = < 0x18401828 >;
			ceva,p1-comwake-params = < 0x614080e >;
			ceva,p1-burst-params = < 0x13084a06 >;
			ceva,p1-retry-params = < 0x96a43ffc >;
			phy-names = "sata-phy";
			phys = < 0x2a 0x01 0x01 0x01 0x7735940 >;
		};

		sdhci@ff160000 {
			u-boot,dm-pre-reloc;
			compatible = "xlnx,zynqmp-8.9a\0arasan,sdhci-8.9a";
			status = "disabled";
			interrupt-parent = < 0x04 >;
			interrupts = < 0x00 0x30 0x04 >;
			reg = < 0x00 0xff160000 0x00 0x1000 >;
			clock-names = "clk_xin\0clk_ahb";
			xlnx,device_id = < 0x00 >;
			#stream-id-cells = < 0x01 >;
			iommus = < 0x0f 0x870 >;
			power-domains = < 0x2b >;
			clocks = < 0x03 0x36 0x03 0x1f >;
		};

		sdhci@ff170000 {
			u-boot,dm-pre-reloc;
			compatible = "xlnx,zynqmp-8.9a\0arasan,sdhci-8.9a";
			status = "okay";
			interrupt-parent = < 0x04 >;
			interrupts = < 0x00 0x31 0x04 >;
			reg = < 0x00 0xff170000 0x00 0x1000 >;
			clock-names = "clk_xin\0clk_ahb";
			xlnx,device_id = < 0x01 >;
			#stream-id-cells = < 0x01 >;
			iommus = < 0x0f 0x871 >;
			power-domains = < 0x2c >;
			clocks = < 0x03 0x37 0x03 0x1f >;
			pinctrl-names = "default";
			pinctrl-0 = < 0x2d >;
			no-1-8-v;
			clock-frequency = < 0xb2cbba8 >;
			xlnx,mio_bank = < 0x01 >;
		};

		pinctrl@ff180000 {
			compatible = "xlnx,pinctrl-zynqmp";
			status = "okay";
			reg = < 0x00 0xff180000 0x00 0x1000 >;

			i2c0-default {
				linux,phandle = < 0x1d >;
				phandle = < 0x1d >;

				mux {
					groups = "i2c0_3_grp";
					function = "i2c0";
				};

				conf {
					groups = "i2c0_3_grp";
					bias-pull-up;
					slew-rate = < 0x01 >;
					io-standard = < 0x01 >;
				};
			};

			i2c0-gpio {
				linux,phandle = < 0x1e >;
				phandle = < 0x1e >;

				mux {
					groups = "gpio0_14_grp\0gpio0_15_grp";
					function = "gpio0";
				};

				conf {
					groups = "gpio0_14_grp\0gpio0_15_grp";
					slew-rate = < 0x01 >;
					io-standard = < 0x01 >;
				};
			};

			i2c1-default {
				linux,phandle = < 0x21 >;
				phandle = < 0x21 >;

				mux {
					groups = "i2c1_4_grp";
					function = "i2c1";
				};

				conf {
					groups = "i2c1_4_grp";
					bias-pull-up;
					slew-rate = < 0x01 >;
					io-standard = < 0x01 >;
				};
			};

			i2c1-gpio {
				linux,phandle = < 0x22 >;
				phandle = < 0x22 >;

				mux {
					groups = "gpio0_16_grp\0gpio0_17_grp";
					function = "gpio0";
				};

				conf {
					groups = "gpio0_16_grp\0gpio0_17_grp";
					slew-rate = < 0x01 >;
					io-standard = < 0x01 >;
				};
			};

			uart0-default {
				linux,phandle = < 0x35 >;
				phandle = < 0x35 >;

				mux {
					groups = "uart0_4_grp";
					function = "uart0";
				};

				conf {
					groups = "uart0_4_grp";
					slew-rate = < 0x01 >;
					io-standard = < 0x01 >;
				};

				conf-rx {
					pins = "MIO18";
					bias-high-impedance;
				};

				conf-tx {
					pins = "MIO19";
					bias-disable;
				};
			};


			usb0-default {
				linux,phandle = < 0x39 >;
				phandle = < 0x39 >;

				mux {
					groups = "usb0_0_grp";
					function = "usb0";
				};

				conf {
					groups = "usb0_0_grp";
					slew-rate = < 0x01 >;
					io-standard = < 0x01 >;
				};

				conf-rx {
					pins = "MIO52\0MIO53\0MIO55";
					bias-high-impedance;
				};

				conf-tx {
					pins = "MIO54\0MIO56\0MIO57\0MIO58\0MIO59\0MIO60\0MIO61\0MIO62\0MIO63";
					bias-disable;
				};
			};

			gem3-default {
				linux,phandle = < 0x19 >;
				phandle = < 0x19 >;

				mux {
					function = "ethernet3";
					groups = "ethernet3_0_grp";
				};

				conf {
					groups = "ethernet3_0_grp";
					slew-rate = < 0x01 >;
					io-standard = < 0x01 >;
				};

				conf-rx {
					pins = "MIO70\0MIO71\0MIO72\0MIO73\0MIO74\0MIO75";
					bias-high-impedance;
					low-power-disable;
				};

				conf-tx {
					pins = "MIO64\0MIO65\0MIO66\0MIO67\0MIO68\0MIO69";
					bias-disable;
					low-power-enable;
				};

				mux-mdio {
					function = "mdio3";
					groups = "mdio3_0_grp";
				};

				conf-mdio {
					groups = "mdio3_0_grp";
					slew-rate = < 0x01 >;
					io-standard = < 0x01 >;
					bias-disable;
				};
			};

			can1-default {
				linux,phandle = < 0x0e >;
				phandle = < 0x0e >;

				mux {
					function = "can1";
					groups = "can1_6_grp";
				};

				conf {
					groups = "can1_6_grp";
					slew-rate = < 0x01 >;
					io-standard = < 0x01 >;
				};

				conf-rx {
					pins = "MIO25";
					bias-high-impedance;
				};

				conf-tx {
					pins = "MIO24";
					bias-disable;
				};
			};

			sdhci1-default {
				linux,phandle = < 0x2d >;
				phandle = < 0x2d >;

				mux {
					groups = "sdio1_0_grp";
					function = "sdio1";
				};

				conf {
					groups = "sdio1_0_grp";
					slew-rate = < 0x01 >;
					io-standard = < 0x01 >;
					bias-disable;
				};

				mux-cd {
					groups = "sdio1_0_cd_grp";
					function = "sdio1_cd";
				};

				conf-cd {
					groups = "sdio1_0_cd_grp";
					bias-high-impedance;
					bias-pull-up;
					slew-rate = < 0x01 >;
					io-standard = < 0x01 >;
				};

				mux-wp {
					groups = "sdio1_0_wp_grp";
					function = "sdio1_wp";
				};

				conf-wp {
					groups = "sdio1_0_wp_grp";
					bias-high-impedance;
					bias-pull-up;
					slew-rate = < 0x01 >;
					io-standard = < 0x01 >;
				};
			};

			gpio-default {
				linux,phandle = < 0x1b >;
				phandle = < 0x1b >;

				mux-sw {
					function = "gpio0";
					groups = "gpio0_22_grp\0gpio0_23_grp";
				};

				conf-sw {
					groups = "gpio0_22_grp\0gpio0_23_grp";
					slew-rate = < 0x01 >;
					io-standard = < 0x01 >;
				};

				mux-msp {
					function = "gpio0";
					groups = "gpio0_13_grp\0gpio0_38_grp";
				};

				conf-msp {
					groups = "gpio0_13_grp\0gpio0_38_grp";
					slew-rate = < 0x01 >;
					io-standard = < 0x01 >;
				};

				conf-pull-up {
					pins = "MIO22\0MIO23";
					bias-pull-up;
				};

				conf-pull-none {
					pins = "MIO13\0MIO38";
					bias-disable;
				};
			};
		};

		smmu@fd800000 {
			compatible = "arm,mmu-500";
			reg = < 0x00 0xfd800000 0x00 0x20000 >;
			#iommu-cells = < 0x01 >;
			status = "disabled";
			#global-interrupts = < 0x01 >;
			interrupt-parent = < 0x04 >;
			interrupts = < 0x00 0x9b 0x04 0x00 0x9b 0x04 0x00 0x9b 0x04 0x00 0x9b 0x04 0x00 0x9b 0x04 0x00 0x9b 0x04 0x00 0x9b 0x04 0x00 0x9b 0x04 0x00 0x9b 0x04 0x00 0x9b 0x04 0x00 0x9b 0x04 0x00 0x9b 0x04 0x00 0x9b 0x04 0x00 0x9b 0x04 0x00 0x9b 0x04 0x00 0x9b 0x04 0x00 0x9b 0x04 >;
			linux,phandle = < 0x0f >;
			phandle = < 0x0f >;
		};

		spi@ff040000 {
			compatible = "cdns,spi-r1p6";
			status = "disabled";
			interrupt-parent = < 0x04 >;
			interrupts = < 0x00 0x13 0x04 >;
			reg = < 0x00 0xff040000 0x00 0x1000 >;
			clock-names = "ref_clk\0pclk";
			#address-cells = < 0x01 >;
			#size-cells = < 0x00 >;
			power-domains = < 0x2e >;
			clocks = < 0x03 0x3a 0x03 0x1f >;
		};

		spi@ff050000 {
			compatible = "cdns,spi-r1p6";
			status = "disabled";
			interrupt-parent = < 0x04 >;
			interrupts = < 0x00 0x14 0x04 >;
			reg = < 0x00 0xff050000 0x00 0x1000 >;
			clock-names = "ref_clk\0pclk";
			#address-cells = < 0x01 >;
			#size-cells = < 0x00 >;
			power-domains = < 0x2f >;
			clocks = < 0x03 0x3b 0x03 0x1f >;
		};

		timer@ff110000 {
			compatible = "cdns,ttc";
			status = "disabled";
			interrupt-parent = < 0x04 >;
			interrupts = < 0x00 0x24 0x04 0x00 0x25 0x04 0x00 0x26 0x04 >;
			reg = < 0x00 0xff110000 0x00 0x1000 >;
			timer-width = < 0x20 >;
			power-domains = < 0x30 >;
		};

		timer@ff120000 {
			compatible = "cdns,ttc";
			status = "disabled";
			interrupt-parent = < 0x04 >;
			interrupts = < 0x00 0x27 0x04 0x00 0x28 0x04 0x00 0x29 0x04 >;
			reg = < 0x00 0xff120000 0x00 0x1000 >;
			timer-width = < 0x20 >;
			power-domains = < 0x31 >;
		};

		timer@ff130000 {
			compatible = "cdns,ttc";
			status = "disabled";
			interrupt-parent = < 0x04 >;
			interrupts = < 0x00 0x2a 0x04 0x00 0x2b 0x04 0x00 0x2c 0x04 >;
			reg = < 0x00 0xff130000 0x00 0x1000 >;
			timer-width = < 0x20 >;
			power-domains = < 0x32 >;
		};

		timer@ff140000 {
			compatible = "cdns,ttc";
			status = "disabled";
			interrupt-parent = < 0x04 >;
			interrupts = < 0x00 0x2d 0x04 0x00 0x2e 0x04 0x00 0x2f 0x04 >;
			reg = < 0x00 0xff140000 0x00 0x1000 >;
			timer-width = < 0x20 >;
			power-domains = < 0x33 >;
		};

		serial@ff000000 {
			u-boot,dm-pre-reloc;
			compatible = "cdns,uart-r1p12\0xlnx,xuartps";
			status = "okay";
			interrupt-parent = < 0x04 >;
			interrupts = < 0x00 0x15 0x04 >;
			reg = < 0x00 0xff000000 0x00 0x1000 >;
			clock-names = "uart_clk\0pclk";
			power-domains = < 0x34 >;
			clocks = < 0x03 0x38 0x03 0x1f >;
			pinctrl-names = "default";
			pinctrl-0 = < 0x35 >;
			device_type = "serial";
			port-number = < 0x00 >;
		};

		serial@ff010000 {
			u-boot,dm-pre-reloc;
			compatible = "cdns,uart-r1p12\0xlnx,xuartps";
			status = "okay";
			interrupt-parent = < 0x04 >;
			interrupts = < 0x00 0x16 0x04 >;
			reg = < 0x00 0xff010000 0x00 0x1000 >;
			clock-names = "uart_clk\0pclk";
			power-domains = < 0x36 >;
			clocks = < 0x03 0x39 0x03 0x1f >;
			pinctrl-names = "default";
			pinctrl-0 = < 0x37 >;
			device_type = "serial";
			port-number = < 0x01 >;
		};

		usb0@ff9d0000 {
			#address-cells = < 0x02 >;
			#size-cells = < 0x02 >;
			status = "okay";
			compatible = "xlnx,zynqmp-dwc3";
			reg = < 0x00 0xff9d0000 0x00 0x100 >;
			clock-names = "bus_clk\0ref_clk";
			power-domains = < 0x38 >;
			ranges;
			nvmem-cells = < 0x27 >;
			nvmem-cell-names = "soc_revision";
			clocks = < 0x03 0x20 0x03 0x22 >;
			pinctrl-names = "default";
			pinctrl-0 = < 0x39 >;
			xlnx,usb-reset = < 0x2faf080 >;

			dwc3@fe200000 {
				compatible = "snps,dwc3";
				status = "okay";
				reg = < 0x00 0xfe200000 0x00 0x40000 >;
				interrupt-parent = < 0x04 >;
				interrupts = < 0x00 0x41 0x04 0x00 0x45 0x04 >;
				#stream-id-cells = < 0x01 >;
				iommus = < 0x0f 0x860 >;
				snps,quirk-frame-length-adjustment = < 0x20 >;
				snps,refclk_fladj;
				snps,enable_guctl1_resume_quirk;
				snps,enable_guctl1_ipd_quirk;
				snps,xhci-stream-quirk;
				dr_mode = "host";
				snps,usb3_lpm_capable;
				phy-names = "usb3-phy";
				phys = < 0x3a 0x04 0x00 0x02 0x18cba80 >;
			};
		};

		usb1@ff9e0000 {
			#address-cells = < 0x02 >;
			#size-cells = < 0x02 >;
			status = "disabled";
			compatible = "xlnx,zynqmp-dwc3";
			reg = < 0x00 0xff9e0000 0x00 0x100 >;
			clock-names = "bus_clk\0ref_clk";
			power-domains = < 0x3b >;
			ranges;
			nvmem-cells = < 0x27 >;
			nvmem-cell-names = "soc_revision";
			clocks = < 0x03 0x21 0x03 0x22 >;

			dwc3@fe300000 {
				compatible = "snps,dwc3";
				status = "disabled";
				reg = < 0x00 0xfe300000 0x00 0x40000 >;
				interrupt-parent = < 0x04 >;
				interrupts = < 0x00 0x46 0x04 0x00 0x4a 0x04 >;
				#stream-id-cells = < 0x01 >;
				iommus = < 0x0f 0x861 >;
				snps,quirk-frame-length-adjustment = < 0x20 >;
				snps,refclk_fladj;
				snps,enable_guctl1_resume_quirk;
				snps,enable_guctl1_ipd_quirk;
				snps,xhci-stream-quirk;
			};
		};

		watchdog@fd4d0000 {
			compatible = "cdns,wdt-r1p2";
			status = "okay";
			interrupt-parent = < 0x04 >;
			interrupts = < 0x00 0x71 0x01 >;
			reg = < 0x00 0xfd4d0000 0x00 0x1000 >;
			timeout-sec = < 0x0a >;
			clocks = < 0x03 0x4b >;
		};

		ams@ffa50000 {
			compatible = "xlnx,zynqmp-ams";
			status = "okay";
			interrupt-parent = < 0x04 >;
			interrupts = < 0x00 0x38 0x04 >;
			interrupt-names = "ams-irq";
			reg = < 0x00 0xffa50000 0x00 0x800 >;
			reg-names = "ams-base";
			#address-cells = < 0x02 >;
			#size-cells = < 0x02 >;
			#io-channel-cells = < 0x01 >;
			ranges;
			clocks = < 0x03 0x46 >;

			ams_ps@ffa50800 {
				compatible = "xlnx,zynqmp-ams-ps";
				status = "okay";
				reg = < 0x00 0xffa50800 0x00 0x400 >;
			};

			ams_pl@ffa50c00 {
				compatible = "xlnx,zynqmp-ams-pl";
				status = "okay";
				reg = < 0x00 0xffa50c00 0x00 0x400 >;
			};
		};

		dp@fd4a0000 {
			compatible = "xlnx,v-dp";
			status = "okay";
			reg = < 0x00 0xfd4a0000 0x00 0x1000 >;
			interrupts = < 0x00 0x77 0x04 >;
			interrupt-parent = < 0x04 >;
			clock-names = "aclk\0aud_clk";
			power-domains = < 0x3c >;
			xlnx,dp-version = "v1.2";
			xlnx,max-lanes = < 0x01 >;
			xlnx,max-link-rate = < 0x83d60 >;
			xlnx,max-bpc = < 0x10 >;
			xlnx,enable-ycrcb;
			xlnx,colormetry = "rgb";
			xlnx,bpc = < 0x08 >;
			xlnx,audio-chan = < 0x02 >;
			xlnx,dp-sub = < 0x0b >;
			xlnx,max-pclock-frequency = < 0x493e0 >;
			clocks = < 0x3d 0x03 0x11 >;
			phy-names = "dp-phy0";
			phys = < 0x3e 0x05 0x00 0x03 0x19bfcc0 >;
			linux,phandle = < 0x0a >;
			phandle = < 0x0a >;
		};

		dp_sub@fd4aa000 {
			compatible = "xlnx,dp-sub";
			status = "okay";
			reg = < 0x00 0xfd4aa000 0x00 0x1000 0x00 0xfd4ab000 0x00 0x1000 0x00 0xfd4ac000 0x00 0x1000 >;
			reg-names = "blend\0av_buf\0aud";
			xlnx,output-fmt = "rgb";
			xlnx,vid-fmt = "yuyv";
			xlnx,gfx-fmt = "rgb565";
			power-domains = < 0x3c >;
			linux,phandle = < 0x0b >;
			phandle = < 0x0b >;
		};

		dma@fd4c0000 {
			compatible = "xlnx,dpdma";
			status = "okay";
			reg = < 0x00 0xfd4c0000 0x00 0x1000 >;
			interrupts = < 0x00 0x7a 0x04 >;
			interrupt-parent = < 0x04 >;
			clock-names = "axi_clk";
			power-domains = < 0x3c >;
			dma-channels = < 0x06 >;
			#dma-cells = < 0x01 >;
			clocks = < 0x03 0x14 >;
			linux,phandle = < 0x09 >;
			phandle = < 0x09 >;

			dma-video0channel {
				compatible = "xlnx,video0";
			};

			dma-video1channel {
				compatible = "xlnx,video1";
			};

			dma-video2channel {
				compatible = "xlnx,video2";
			};

			dma-graphicschannel {
				compatible = "xlnx,graphics";
			};

			dma-audio0channel {
				compatible = "xlnx,audio0";
			};

			dma-audio1channel {
				compatible = "xlnx,audio1";
			};
		};
	};

	fclk0 {
		status = "disabled";
		compatible = "xlnx,fclk";
		clocks = < 0x03 0x47 >;
	};

	fclk1 {
		status = "disabled";
		compatible = "xlnx,fclk";
		clocks = < 0x03 0x48 >;
	};

	fclk2 {
		status = "disabled";
		compatible = "xlnx,fclk";
		clocks = < 0x03 0x49 >;
	};

	fclk3 {
		status = "disabled";
		compatible = "xlnx,fclk";
		clocks = < 0x03 0x4a >;
	};

	pss_ref_clk {
		u-boot,dm-pre-reloc;
		compatible = "fixed-clock";
		#clock-cells = < 0x00 >;
		clock-frequency = < 0x1fc9350 >;
		linux,phandle = < 0x3f >;
		phandle = < 0x3f >;
	};

	video_clk {
		u-boot,dm-pre-reloc;
		compatible = "fixed-clock";
		#clock-cells = < 0x00 >;
		clock-frequency = < 0x19bfcc0 >;
		linux,phandle = < 0x40 >;
		phandle = < 0x40 >;
	};

	pss_alt_ref_clk {
		u-boot,dm-pre-reloc;
		compatible = "fixed-clock";
		#clock-cells = < 0x00 >;
		clock-frequency = < 0x00 >;
		linux,phandle = < 0x41 >;
		phandle = < 0x41 >;
	};

	gt_crx_ref_clk {
		u-boot,dm-pre-reloc;
		compatible = "fixed-clock";
		#clock-cells = < 0x00 >;
		clock-frequency = < 0x66ff300 >;
		linux,phandle = < 0x43 >;
		phandle = < 0x43 >;
	};

	aux_ref_clk {
		u-boot,dm-pre-reloc;
		compatible = "fixed-clock";
		#clock-cells = < 0x00 >;
		clock-frequency = < 0x19bfcc0 >;
		linux,phandle = < 0x42 >;
		phandle = < 0x42 >;
	};

	clkc {
		u-boot,dm-pre-reloc;
		#clock-cells = < 0x01 >;
		compatible = "xlnx,zynqmp-clkc";
		clocks = < 0x3f 0x40 0x41 0x42 0x43 >;
		clock-names = "pss_ref_clk\0video_clk\0pss_alt_ref_clk\0aux_ref_clk\0gt_crx_ref_clk";
		clock-output-names = "iopll\0rpll\0apll\0dpll\0vpll\0iopll_to_fpd\0rpll_to_fpd\0apll_to_lpd\0dpll_to_lpd\0vpll_to_lpd\0acpu\0acpu_half\0dbf_fpd\0dbf_lpd\0dbg_trace\0dbg_tstmp\0dp_video_ref\0dp_audio_ref\0dp_stc_ref\0gdma_ref\0dpdma_ref\0ddr_ref\0sata_ref\0pcie_ref\0gpu_ref\0gpu_pp0_ref\0gpu_pp1_ref\0topsw_main\0topsw_lsbus\0gtgref0_ref\0lpd_switch\0lpd_lsbus\0usb0_bus_ref\0usb1_bus_ref\0usb3_dual_ref\0usb0\0usb1\0cpu_r5\0cpu_r5_core\0csu_spb\0csu_pll\0pcap\0iou_switch\0gem_tsu_ref\0gem_tsu\0gem0_ref\0gem1_ref\0gem2_ref\0gem3_ref\0gem0_tx\0gem1_tx\0gem2_tx\0gem3_tx\0qspi_ref\0sdio0_ref\0sdio1_ref\0uart0_ref\0uart1_ref\0spi0_ref\0spi1_ref\0nand_ref\0i2c0_ref\0i2c1_ref\0can0_ref\0can1_ref\0can0\0can1\0dll_ref\0adma_ref\0timestamp_ref\0ams_ref\0pl0\0pl1\0pl2\0pl3\0wdt";
		linux,phandle = < 0x03 >;
		phandle = < 0x03 >;
	};

	dp_aclk {
		compatible = "fixed-clock";
		#clock-cells = < 0x00 >;
		clock-frequency = < 0x5f5e100 >;
		clock-accuracy = < 0x64 >;
		linux,phandle = < 0x3d >;
		phandle = < 0x3d >;
	};

	gpio-keys {
		compatible = "gpio-keys";
		#address-cells = < 0x01 >;
		#size-cells = < 0x00 >;
		autorepeat;

		sw19 {
			label = "sw19";
			gpios = < 0x1f 0x16 0x00 >;
			linux,code = < 0x6c >;
			gpio-key,wakeup;
			autorepeat;
		};
	};

	leds {
		compatible = "gpio-leds";

		heartbeat_led {
			label = "heartbeat";
			gpios = < 0x1f 0x17 0x00 >;
			linux,default-trigger = "heartbeat";
		};
	};

	amba_pl@0 {
		#address-cells = < 0x02 >;
		#size-cells = < 0x02 >;
		compatible = "simple-bus";
		ranges;

		AXI_PerfectTranslator@b0000000 {
			compatible = "xlnx,AXI-PerfectTranslator-1.0";
			reg = < 0x00 0xb0000000 0x00 0x10000000 >;
			xlnx,m00-axi-addr-width = < 0x31 >;
			xlnx,m00-axi-aruser-width = < 0x01 >;
			xlnx,m00-axi-awuser-width = < 0x01 >;
			xlnx,m00-axi-burst-len = < 0x10 >;
			xlnx,m00-axi-buser-width = < 0x01 >;
			xlnx,m00-axi-data-width = < 0x80 >;
			xlnx,m00-axi-id-width = < 0x06 >;
			xlnx,m00-axi-ruser-width = < 0x01 >;
			xlnx,m00-axi-target-slave-base-addr = < 0x40000000 >;
			xlnx,m00-axi-wuser-width = < 0x01 >;
			xlnx,s00-axi-addr-width = < 0x28 >;
			xlnx,s00-axi-aruser-width = < 0x10 >;
			xlnx,s00-axi-awuser-width = < 0x10 >;
			xlnx,s00-axi-buser-width = < 0x00 >;
			xlnx,s00-axi-data-width = < 0x80 >;
			xlnx,s00-axi-id-width = < 0x10 >;
			xlnx,s00-axi-ruser-width = < 0x00 >;
			xlnx,s00-axi-wuser-width = < 0x00 >;
		};

		MemorEDF@80000000 {
			compatible = "xlnx,MemorEDF-1.0";
			reg = < 0x00 0x80000000 0x00 0x10000 0xa0000000 0x10000000 >;
			xlnx,m00-axi-addr-width = < 0x28 >;
			xlnx,m00-axi-aruser-width = < 0x10 >;
			xlnx,m00-axi-awuser-width = < 0x10 >;
			xlnx,m00-axi-burst-len = < 0x01 >;
			xlnx,m00-axi-data-width = < 0x80 >;
			xlnx,m00-axi-id-width = < 0x10 >;
			xlnx,s00-axi-addr-width = < 0x28 >;
			xlnx,s00-axi-aruser-width = < 0x10 >;
			xlnx,s00-axi-awuser-width = < 0x10 >;
			xlnx,s00-axi-data-width = < 0x80 >;
			xlnx,s00-axi-id-width = < 0x10 >;
			xlnx,s01-axi-addr-width = < 0x28 >;
			xlnx,s01-axi-aruser-width = < 0x10 >;
			xlnx,s01-axi-awuser-width = < 0x10 >;
			xlnx,s01-axi-data-width = < 0x80 >;
			xlnx,s01-axi-id-width = < 0x10 >;
		};

		PERIPHERAL@ff380000 {
			compatible = "xlnx,PERIPHERAL-1.0";
			reg = < 0x00 0xff380000 0x00 0x80000 >;
		};

		PERIPHERAL@ff990000 {
			compatible = "xlnx,PERIPHERAL-1.0";
			reg = < 0x00 0xff990000 0x00 0x10000 >;
		};
	};

	chosen {
		bootargs = "earlycon clk_ignore_unused root=/dev/mmcblk0p2 rw rootwait";
		stdout-path = "serial0:115200n8";
	};

	aliases {
		ethernet0 = "/amba/ethernet@ff0e0000";
		serial0 = "/amba/serial@ff000000";
		serial1 = "/amba/serial@ff010000";
		spi0 = "/amba/spi@ff0f0000";
	};

	memory {
		device_type = "memory";
		reg = < 0x00 0x00 0x00 0x80000000 0x08 0x00 0x00 0x80000000 >;
	};
};
